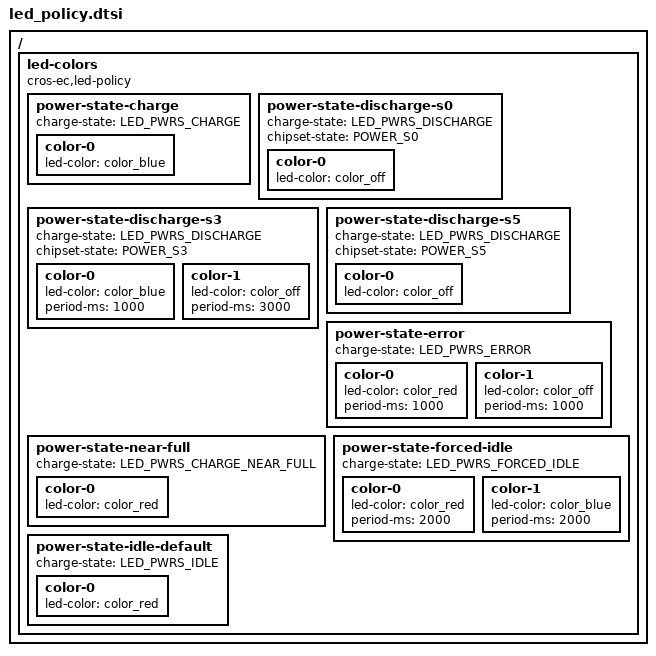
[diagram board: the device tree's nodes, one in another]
/* Copyright 2022 The ChromiumOS Authors
 * Use of this source code is governed by a BSD-style license that can be
 * found in the LICENSE file.
 */

/ {
	led-colors {
		compatible = "cros-ec,led-policy";

		power-state-charge {
			charge-state = "LED_PWRS_CHARGE";

			color-0 {
				led-color = <&color_blue>;
			};
		};

		power-state-discharge-s0 {
			charge-state = "LED_PWRS_DISCHARGE";
			chipset-state = "POWER_S0";

			color-0 {
				led-color = <&color_off>;
			};
		};

		power-state-discharge-s3 {
			charge-state = "LED_PWRS_DISCHARGE";
			chipset-state = "POWER_S3";

			/* Blue 1 sec, off 3 sec */
			color-0 {
				led-color = <&color_blue>;
				period-ms = <1000>;
			};
			color-1 {
				led-color = <&color_off>;
				period-ms = <3000>;
			};
		};

		power-state-discharge-s5 {
			charge-state = "LED_PWRS_DISCHARGE";
			chipset-state = "POWER_S5";

			color-0 {
				led-color = <&color_off>;
			};
		};

		power-state-error {
			charge-state = "LED_PWRS_ERROR";

			/* Red 1 sec, off 1 sec */
			color-0 {
				led-color = <&color_red>;
				period-ms = <1000>;
			};
			color-1 {
				led-color = <&color_off>;
				period-ms = <1000>;
			};
		};

		power-state-near-full {
			charge-state = "LED_PWRS_CHARGE_NEAR_FULL";

			color-0 {
				led-color = <&color_red>;
			};
		};

		power-state-forced-idle {
			charge-state = "LED_PWRS_FORCED_IDLE";

			/* Red 2 sec, Blue 2 sec */
			color-0 {
				led-color = <&color_red>;
				period-ms = <2000>;
			};
			color-1 {
				led-color = <&color_blue>;
				period-ms = <2000>;
			};
		};

		power-state-idle-default {
			charge-state = "LED_PWRS_IDLE";

			color-0 {
				led-color = <&color_red>;
			};
		};
	};
};
